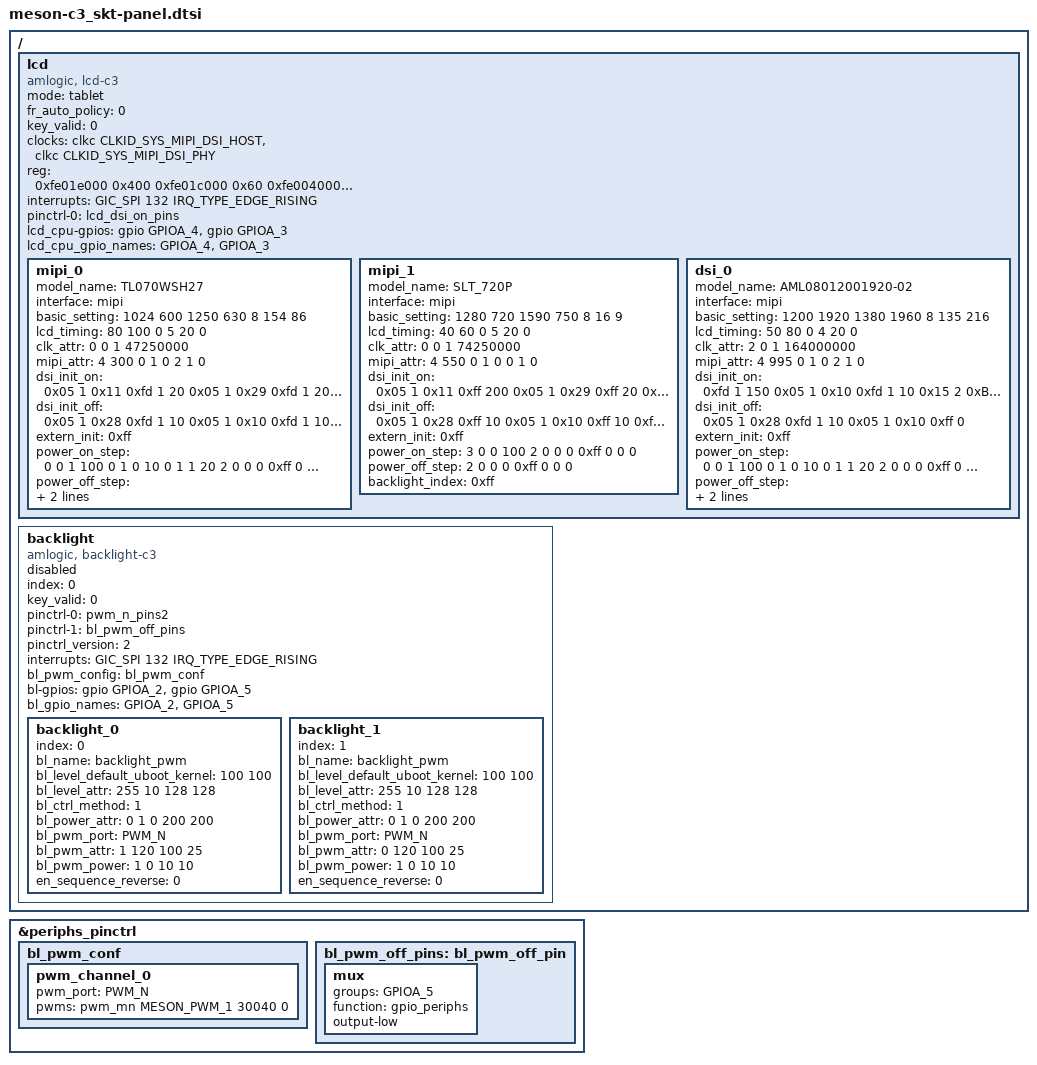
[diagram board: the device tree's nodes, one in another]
// SPDX-License-Identifier: (GPL-2.0+ OR MIT)
/*
 * Copyright (c) 2019 Amlogic, Inc. All rights reserved.
 */

/ {
	lcd: lcd {
		compatible = "amlogic, lcd-c3";
		status = "okay";
		mode = "tablet";
		fr_auto_policy = <0>; /* 0=disable, 1=enable */
		key_valid = <0>;
		clocks = <&clkc CLKID_SYS_MIPI_DSI_HOST>, <&clkc CLKID_SYS_MIPI_DSI_PHY>;
		clock-names = "dsi_host_gate", "dsi_phy_gate";
		reg = <0xfe01e000 0x400    /* mipi-dsi host */
			0xfe01c000 0x60     /* mipi-dsi phy */
			0xfe004000 0x400>;  /* pad ctrl */
		interrupts = <GIC_SPI 132 IRQ_TYPE_EDGE_RISING>;
		interrupt-names = "vsync";
		pinctrl-names = "dsi_on";
		pinctrl-0 = <&lcd_dsi_on_pins>;

		/* power type:(0=cpu_gpio, 2=signal, 3=extern, 0xff=ending) */
		/* power index:(gpios_index, or extern_index, 0xff=invalid) */
		/* power value:(0=output low, 1=output high, 2=input) */
		/* power delay:(unit in ms) */
		lcd_cpu-gpios = <&gpio GPIOA_4 GPIO_ACTIVE_HIGH>, <&gpio GPIOA_3 GPIO_ACTIVE_HIGH>;
		lcd_cpu_gpio_names = "GPIOA_4","GPIOA_3";

		mipi_0{
			model_name = "TL070WSH27";
			interface = "mipi";
			basic_setting = <1024 600 /*h_active, v_active*/
				1250 630 /*h_period, v_period*/
				8 /*lcd_bits*/
				154 86>; /*screen_widht, screen_height*/
			lcd_timing = <80 100 0 /*hs_width, hs_bp, hs_pol*/
				5 20 0>; /*vs_width, vs_bp, vs_pol*/
			clk_attr = <0 /*fr_adj_type(0=clk, 1=htotal, 2=vtotal)*/
				0 /*clk_ss_level */
				1 /*clk_auto_generate*/
				47250000>; /*pixel_clk(unit in Hz)*/
			mipi_attr = <4 /*lane_num*/
				300 /*bit_rate_max(MHz)*/
				0 /*unused*/
				1 /*operation_mode_init(0=video, 1=command)*/
				0 /*operation_mode_display(0=video, 1=command)*/
				2 /*video_mode_type: 0=sync_pulse,1=sync_event,2=burst)*/
				1 /*clk_always_hs(0=disable,1=enable)*/
				0>; /*unused*/

			/* dsi_init: data_type, num, data... */
			dsi_init_on = <0x05 1 0x11
					0xfd 1 20     /*delay(ms)*/
					0x05 1 0x29
					0xfd 1 20     /*delay(ms)*/
					0xff 0>; /*ending*/
			dsi_init_off = <0x05 1 0x28
					0xfd 1 10     /*delay(ms)*/
					0x05 1 0x10
					0xfd 1 10     /*delay(ms)*/
					0xff 0>; /*ending*/
			extern_init = <0xff>; /*0xff for invalid*/

			/* power step: type, index, value, delay(ms) */
			power_on_step = <
				0 0 1 100
				0 1 0 10
				0 1 1 20
				2 0 0 0
				0xff 0 0 0>; /*ending*/
			power_off_step = <
				2 0 0 50
				0 1 0 10
				0 0 0 100
				0xff 0 0 0>; /*ending*/
			backlight_index = <0>;
		};
		mipi_1{
			model_name = "SLT_720P";
			interface = "mipi";
			basic_setting = <1280 720 /*h_active, v_active*/
				1590 750 /*h_period, v_period*/
				8 /*lcd_bits*/
				16 9>; /*screen_widht, screen_height*/
			lcd_timing = <40 60 0 /*hs_width,hs_bp,hs_pol*/
				5 20 0>; /*vs_width,vs_bp,vs_pol*/
			clk_attr = <0 /*fr_adj_type(0=clock,1=htotal,2=vtotal)*/
				0 /*clk_ss: [0:7]:level, [8:11]:freq, [12:15]: mode*/
				1 /*clk_auto_generate*/
				74250000>; /*pixel_clk(unit in Hz)*/
			mipi_attr = <4 /*lane_num*/
				550 /*bit_rate_max(MHz)*/
				0 /*unused*/
				1 /*operation_mode_init(0=video, 1=command)*/
				0 /*operation_mode_display(0=video, 1=command)*/
				0 /*video_mode_type: 0=sync_pulse,1=sync_event,2=burst)*/
				1 /*clk_always_hs(0=disable,1=enable)*/
				0>; /*unused*/
				/* dsi_init: data_type, num, data... */
			dsi_init_on = <
				0x05 1 0x11
				0xff 200
				0x05 1 0x29
				0xff 20
				0xff 0xff>; /* ending flag */
			dsi_init_off = <
				0x05 1 0x28
				0xff 10
				0x05 1 0x10
				0xff 10
				0xff 0xff>; /* ending flag */
				/* extern_init: 0xff for invalid */
			extern_init = <0xff>;
				/* power step: type,index,value,delay(ms) */
			power_on_step = <3 0 0 100
					2 0 0 0
					0xff 0 0 0>;
			power_off_step = <2 0 0 0
					0xff 0 0 0>;
			backlight_index = <0xff>;
		};

		dsi_0{
			model_name = "AML08012001920-02";
			interface = "mipi";
			/*h_active, v_active, h_period, v_period, color_bit, width, height*/
			basic_setting = <1200 1920 1380 1960 8 135 216>;
			/*hs_width, hs_bp, hs_pol, vs_width, vs_bp, vs_pol*/
			lcd_timing = <50 80 0 4 20 0>;
			clk_attr = <2 0 1 164000000>;
			/* <lane, bit_rate, /, mode_init, mode_disp, video_mode, clk_hs, />*/
			mipi_attr = <4 995 0 1 0 2 1 0>;
			/* dsi_init: data_type, num, data... */
			dsi_init_on = <
				0xfd 1 150
				0x05 1 0x10
				0xfd 1 10
				0x15 2 0xB0 0x05 0x15 2 0xB3 0x52 0x15 2 0xB0 0x01 0x15 2 0xC8 0x00
				0x15 2 0xC9 0x00 0x15 2 0xCC 0x26 0x15 2 0xCD 0x26 0x15 2 0xDC 0x00
				0x15 2 0xDD 0x00 0x15 2 0xE0 0x26 0x15 2 0xE1 0x26 0x15 2 0xB0 0x03
				0x15 2 0xC3 0x2A 0x15 2 0xE7 0x2A 0x15 2 0xC5 0x2A 0x15 2 0xDE 0x2A
				0x15 2 0xB0 0x00 0x15 2 0xB6 0x03 0x15 2 0xBA 0x87 0x15 2 0xBD 0x78
				0x15 2 0xBF 0x15 0x15 2 0xC0 0x12 0x15 2 0xC2 0x0C 0x15 2 0xC3 0x02
				0x15 2 0xC4 0x0C 0x15 2 0xC5 0x02 0x15 2 0xB0 0x06 0x15 2 0xC0 0xA5
				0x15 2 0xD5 0x20 0x15 2 0xC0 0x00
				0x15 2 0xB0 0x02 /* page2 */
				0x15 2 0xC0 0x00 0x15 2 0xC1 0x02 0x15 2 0xC2 0x06 0x15 2 0xC3 0x16
				0x15 2 0xC4 0x0E 0x15 2 0xC5 0x18 0x15 2 0xC6 0x26 0x15 2 0xC7 0x32
				0x15 2 0xC8 0x3F 0x15 2 0xC9 0x3F 0x15 2 0xCA 0x3F 0x15 2 0xCB 0x3F
				0x15 2 0xCC 0x3D 0x15 2 0xCD 0x2F 0x15 2 0xCE 0x2F 0x15 2 0xCF 0x2F
				0x15 2 0xD0 0x07 0x15 2 0xD2 0x00 0x15 2 0xD3 0x02 0x15 2 0xD4 0x06
				0x15 2 0xD5 0x12 0x15 2 0xD6 0x0A 0x15 2 0xD7 0x14 0x15 2 0xD8 0x22
				0x15 2 0xD9 0x2E 0x15 2 0xDA 0x3D 0x15 2 0xDB 0x3F 0x15 2 0xDC 0x3F
				0x15 2 0xDD 0x3F 0x15 2 0xDE 0x3D 0x15 2 0xDF 0x2F 0x15 2 0xE0 0x2F
				0x15 2 0xE1 0x2F 0x15 2 0xE2 0x07
				0x15 2 0xB0 0x07 /* page7 */
				0x15 2 0xB1 0x00 0x15 2 0xB2 0x19 0x15 2 0xB3 0x31 0x15 2 0xB4 0x5A
				0x15 2 0xB5 0x7C 0x15 2 0xB6 0x9C 0x15 2 0xB7 0xD3 0x15 2 0xB8 0x0E
				0x15 2 0xB9 0x7D 0x15 2 0xBA 0xE0 0x15 2 0xBB 0x7A 0x15 2 0xBC 0xE6
				0x15 2 0xBD 0xE9 0x15 2 0xBE 0x41 0x15 2 0xBF 0x91 0x15 2 0xC0 0xB0
				0x15 2 0xC1 0xCF 0x15 2 0xC2 0xDC 0x15 2 0xC3 0xE9 0x15 2 0xC4 0xEF
				0x15 2 0xC5 0xF5 0x15 2 0xC6 0xFA 0x15 2 0xC7 0xFB 0x15 2 0xC8 0xFC
				0x15 2 0xC9 0x00 0x15 2 0xCA 0x01 0x15 2 0xCB 0x5A 0x15 2 0xCC 0xBF
				0x15 2 0xCD 0xFF 0x15 2 0xCE 0xFF
				0x15 2 0xB0 0x08 /* page8 */
				0x15 2 0xB1 0x00 0x15 2 0xB2 0x19 0x15 2 0xB3 0x31 0x15 2 0xB4 0x5A
				0x15 2 0xB5 0x7C 0x15 2 0xB6 0x9C 0x15 2 0xB7 0xD3 0x15 2 0xB8 0x0E
				0x15 2 0xB9 0x7D 0x15 2 0xBA 0xE0 0x15 2 0xBB 0x7A 0x15 2 0xBC 0xE6
				0x15 2 0xBD 0xE9 0x15 2 0xBE 0x41 0x15 2 0xBF 0x91 0x15 2 0xC0 0xB0
				0x15 2 0xC1 0xCF 0x15 2 0xC2 0xDC 0x15 2 0xC3 0xE9 0x15 2 0xC4 0xEF
				0x15 2 0xC5 0xF5 0x15 2 0xC6 0xFA 0x15 2 0xC7 0xFB 0x15 2 0xC8 0xFC
				0x15 2 0xC9 0x00 0x15 2 0xCA 0x01 0x15 2 0xCB 0x5A 0x15 2 0xCC 0xBF
				0x15 2 0xCD 0xFF 0x15 2 0xCE 0xFF
				0x15 2 0xB0 0x09 /* page9 */
				0x15 2 0xB1 0x00 0x15 2 0xB2 0x19 0x15 2 0xB3 0x31 0x15 2 0xB4 0x5A
				0x15 2 0xB5 0x7C 0x15 2 0xB6 0x9C 0x15 2 0xB7 0xD3 0x15 2 0xB8 0x0E
				0x15 2 0xB9 0x7D 0x15 2 0xBA 0xE0 0x15 2 0xBB 0x7A 0x15 2 0xBC 0xE6
				0x15 2 0xBD 0xE9 0x15 2 0xBE 0x41 0x15 2 0xBF 0x91 0x15 2 0xC0 0xB0
				0x15 2 0xC1 0xCF 0x15 2 0xC2 0xDC 0x15 2 0xC3 0xE9 0x15 2 0xC4 0xEF
				0x15 2 0xC5 0xF5 0x15 2 0xC6 0xFA 0x15 2 0xC7 0xFB 0x15 2 0xC8 0xFC
				0x15 2 0xC9 0x00 0x15 2 0xCA 0x01 0x15 2 0xCB 0x5A 0x15 2 0xCC 0xBF
				0x15 2 0xCD 0xFF 0x15 2 0xCE 0xFF
				0x15 2 0xB0 0x0A /* page10 */
				0x15 2 0xB1 0x00 0x15 2 0xB2 0x19 0x15 2 0xB3 0x31 0x15 2 0xB4 0x5A
				0x15 2 0xB5 0x7C 0x15 2 0xB6 0x9C 0x15 2 0xB7 0xD3 0x15 2 0xB8 0x0E
				0x15 2 0xB9 0x7D 0x15 2 0xBA 0xE0 0x15 2 0xBB 0x7A 0x15 2 0xBC 0xE6
				0x15 2 0xBD 0xE9 0x15 2 0xBE 0x41 0x15 2 0xBF 0x91 0x15 2 0xC0 0xB0
				0x15 2 0xC1 0xCF 0x15 2 0xC2 0xDC 0x15 2 0xC3 0xE9 0x15 2 0xC4 0xEF
				0x15 2 0xC5 0xF5 0x15 2 0xC6 0xFA 0x15 2 0xC7 0xFC 0x15 2 0xC8 0xFC
				0x15 2 0xC9 0x00 0x15 2 0xCA 0x01 0x15 2 0xCB 0x5A 0x15 2 0xCC 0xBF
				0x15 2 0xCD 0xFF 0x15 2 0xCE 0xFF
				0x15 2 0xB0 0x0B /* page11 */
				0x15 2 0xB1 0x00 0x15 2 0xB2 0x19 0x15 2 0xB3 0x31 0x15 2 0xB4 0x5A
				0x15 2 0xB5 0x7C 0x15 2 0xB6 0x9C 0x15 2 0xB7 0xD3 0x15 2 0xB8 0x0E
				0x15 2 0xB9 0x7D 0x15 2 0xBA 0xE0 0x15 2 0xBB 0x7A 0x15 2 0xBC 0xE6
				0x15 2 0xBD 0xE9 0x15 2 0xBE 0x41 0x15 2 0xBF 0x91 0x15 2 0xC0 0xB0
				0x15 2 0xC1 0xCF 0x15 2 0xC2 0xDC 0x15 2 0xC3 0xE9 0x15 2 0xC4 0xEF
				0x15 2 0xC5 0xF5 0x15 2 0xC6 0xFA 0x15 2 0xC7 0xFC 0x15 2 0xC8 0xFC
				0x15 2 0xC9 0x00 0x15 2 0xCA 0x01 0x15 2 0xCB 0x5A 0x15 2 0xCC 0xBF
				0x15 2 0xCD 0xFF 0x15 2 0xCE 0xFF
				0x15 2 0xB0 0x0C /* page12 */
				0x15 2 0xB1 0x00 0x15 2 0xB2 0x19 0x15 2 0xB3 0x31 0x15 2 0xB4 0x5A
				0x15 2 0xB5 0x7C 0x15 2 0xB6 0x9C 0x15 2 0xB7 0xD3 0x15 2 0xB8 0x0E
				0x15 2 0xB9 0x7D 0x15 2 0xBA 0xE0 0x15 2 0xBB 0x7A 0x15 2 0xBC 0xE6
				0x15 2 0xBD 0xE9 0x15 2 0xBE 0x41 0x15 2 0xBF 0x91 0x15 2 0xC0 0xB0
				0x15 2 0xC1 0xCF 0x15 2 0xC2 0xDC 0x15 2 0xC3 0xE9 0x15 2 0xC4 0xEF
				0x15 2 0xC5 0xF5 0x15 2 0xC6 0xFA 0x15 2 0xC7 0xFC 0x15 2 0xC8 0xFC
				0x15 2 0xC9 0x00 0x15 2 0xCA 0x01 0x15 2 0xCB 0x5A 0x15 2 0xCC 0xBF
				0x15 2 0xCD 0xFF 0x15 2 0xCE 0xFF
				0xfd 1 10
				0x05 1 0x11
				0xfd 1 100
				0x05 1 0x29
				0xfd 1 50
				0xff 0>; /*ending*/
			dsi_init_off = <
				0x05 1 0x28
				0xfd 1 10
				0x05 1 0x10
				0xff 0>;
			extern_init = <0xff>; /*0xff for invalid*/

			/* power step: type, index, value, delay(ms) */
			power_on_step = <
				0 0 1 100
				0 1 0 10
				0 1 1 20
				2 0 0 0
				0xff 0 0 0>; /*ending*/
			power_off_step = <
				2 0 0 50
				0 1 0 10
				0 0 0 0
				0xff 0 0 0>; /*ending*/
			backlight_index = <0x1>;
		};

	};

	backlight{
		compatible = "amlogic, backlight-c3";
		status = "disabled";
		index = <0>;
		key_valid = <0>;
		pinctrl-names = "pwm_on", "pwm_off";
		pinctrl-0 = <&pwm_n_pins2>;
		pinctrl-1 = <&bl_pwm_off_pins>;
		pinctrl_version = <2>; /* for uboot */
		interrupts = <GIC_SPI 132 IRQ_TYPE_EDGE_RISING>;
		interrupt-names = "vsync";
		bl_pwm_config = <&bl_pwm_conf>;

		/* pwm port: PWM_A, PWM_B, PWM_C, PWM_D, PWM_E, PWM_F, PWM_VS*/
		/* power index:(point gpios_index, 0xff=invalid) */
		/* power value:(0=output low, 1=output high, 2=input) */
		/* power delay:(unit in ms) */
		bl-gpios = <&gpio GPIOA_2 GPIO_ACTIVE_HIGH
			&gpio GPIOA_5 GPIO_ACTIVE_HIGH>;
		bl_gpio_names = "GPIOA_2","GPIOA_5";

		backlight_0{
			index = <0>;
			bl_name = "backlight_pwm";
			bl_level_default_uboot_kernel = <100 100>;
			bl_level_attr = <255 10 /*max, min*/
				128 128>; /*mid, mid_mapping*/
			bl_ctrl_method = <1>; /*1=pwm,2=pwm_combo,3=ldim*/
			bl_power_attr = <0 /*en_gpio_index*/
				1 0 /*on_value, off_value*/
				200 200>; /*on_delay(ms), off_delay(ms)*/
			bl_pwm_port = "PWM_N";
			bl_pwm_attr = <1 /*pwm_method(0=negative, 1=positvie)*/
				120 /*pwm_freq(pwm:Hz, pwm_vs:multiple of vs)*/
				100 25>; /*duty_max(%), duty_min(%)*/
			bl_pwm_power = <1 0 /*pwm_gpio_index, pwm_gpio_off*/
				10 10>; /*pwm_on_delay(ms), pwm_off_delay(ms)*/
			en_sequence_reverse = <0>; /* 1 for reverse */
		};
		backlight_1{
			index = <1>;
			bl_name = "backlight_pwm";
			bl_level_default_uboot_kernel = <100 100>;
			bl_level_attr = <255 10 /*max, min*/
				128 128>; /*mid, mid_mapping*/
			bl_ctrl_method = <1>; /*1=pwm,2=pwm_combo,3=ldim*/
			bl_power_attr = <0 /*en_gpio_index*/
				1 0 /*on_value, off_value*/
				200 200>; /*on_delay(ms), off_delay(ms)*/
			bl_pwm_port = "PWM_N";
			bl_pwm_attr = <0 /*pwm_method(0=negative, 1=positvie)*/
				120 /*pwm_freq(pwm:Hz, pwm_vs:multiple of vs)*/
				100 25>; /*duty_max(%), duty_min(%)*/
			bl_pwm_power = <1 0 /*pwm_gpio_index, pwm_gpio_off*/
				10 10>; /*pwm_on_delay(ms), pwm_off_delay(ms)*/
			en_sequence_reverse = <0>; /* 1 for reverse */
		};

	};
}; /* end of / */

&periphs_pinctrl {
	bl_pwm_conf:bl_pwm_conf{
		pwm_channel_0 {
			pwm_port = "PWM_N";
			pwms = <&pwm_mn MESON_PWM_1 30040 0>;
		};
	};
	bl_pwm_off_pins:bl_pwm_off_pin {
		mux {
			groups = "GPIOA_5";
			function = "gpio_periphs";
			output-low;
		};
	};
};
